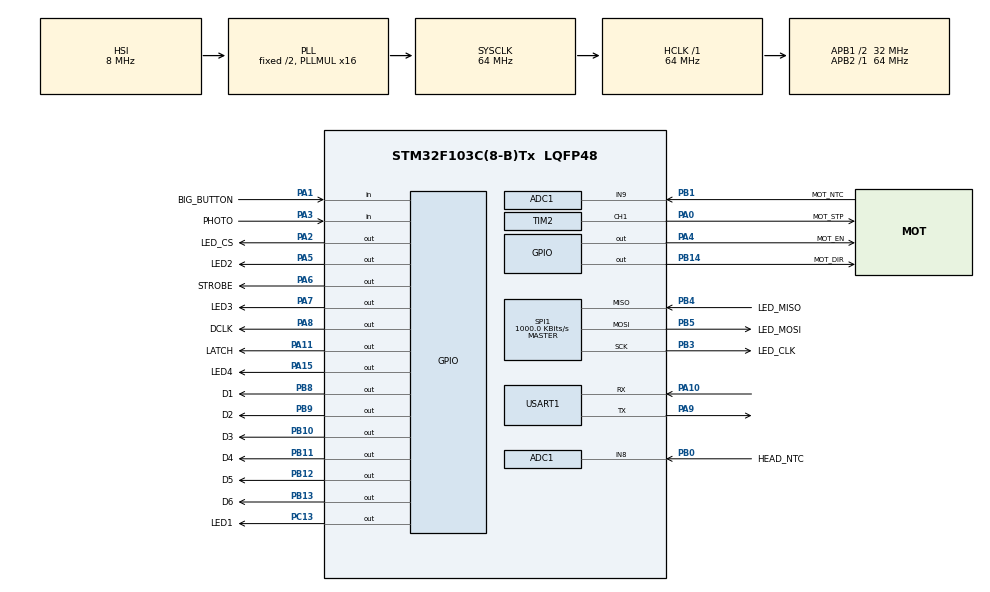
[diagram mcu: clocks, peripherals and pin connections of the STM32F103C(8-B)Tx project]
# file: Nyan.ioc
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ADC1.Channel-0\#ChannelRegularConversion=ADC_CHANNEL_8
ADC1.NbrOfConversionFlag=1
ADC1.Rank-0\#ChannelRegularConversion=1
ADC1.SamplingTime-0\#ChannelRegularConversion=ADC_SAMPLETIME_1CYCLE_5
ADC1.master=1
Dma.Request0=USART1_RX
Dma.USART1_RX.0.Direction=DMA_PERIPH_TO_MEMORY
Dma.USART1_RX.0.Instance=DMA1_Channel5
Dma.USART1_RX.0.MemDataAlignment=DMA_MDATAALIGN_BYTE
Dma.USART1_RX.0.MemInc=DMA_MINC_ENABLE
Dma.USART1_RX.0.Mode=DMA_NORMAL
Dma.USART1_RX.0.PeriphDataAlignment=DMA_PDATAALIGN_BYTE
Dma.USART1_RX.0.PeriphInc=DMA_PINC_DISABLE
Dma.USART1_RX.0.Priority=DMA_PRIORITY_LOW
Mcu.Family=STM32F1
Mcu.Name=STM32F103C(8-B)Tx
Mcu.Package=LQFP48
NVIC.DMA1_Channel5_IRQn=true\:0\:0\:false\:false\:true\:false\:true
NVIC.PriorityGroup=NVIC_PRIORITYGROUP_4
NVIC.TIM2_IRQn=true\:0\:0\:false\:false\:true\:true\:true
NVIC.TIM3_IRQn=true\:0\:0\:false\:false\:true\:true\:true
PA0-WKUP.GPIO_Label=MOT_STP
PA0-WKUP.Signal=S_TIM2_CH1_ETR
PA1.GPIO_Label=BIG_BUTTON
PA1.Signal=GPIO_Input
PA10.Mode=Asynchronous
PA10.Signal=USART1_RX
PA11.GPIO_Label=LATCH
PA11.Signal=GPIO_Output
PA13.Mode=Serial_Wire
PA13.Signal=SYS_JTMS-SWDIO
PA14.Mode=Serial_Wire
PA14.Signal=SYS_JTCK-SWCLK
PA15.GPIO_Label=LED4
PA15.Signal=GPIO_Output
PA2.GPIO_Label=LED_CS
PA2.Signal=GPIO_Output
PA3.GPIO_Label=PHOTO
PA3.Signal=GPIO_Input
PA4.GPIO_Label=MOT_EN
PA4.Signal=GPIO_Output
PA5.GPIO_Label=LED2
PA5.Signal=GPIO_Output
PA6.GPIO_Label=STROBE
PA6.Signal=GPIO_Output
PA7.GPIO_Label=LED3
PA7.Signal=GPIO_Output
PA8.GPIO_Label=DCLK
PA8.Signal=GPIO_Output
PA9.Mode=Asynchronous
PA9.Signal=USART1_TX
PB0.GPIO_Label=HEAD_NTC
PB0.Signal=ADCx_IN8
PB1.GPIO_Label=MOT_NTC
PB1.Signal=ADCx_IN9
PB10.GPIO_Label=D3
PB10.Signal=GPIO_Output
PB11.GPIO_Label=D4
PB11.Signal=GPIO_Output
PB12.GPIO_Label=D5
PB12.Signal=GPIO_Output
PB13.GPIO_Label=D6
PB13.Signal=GPIO_Output
PB14.GPIO_Label=MOT_DIR
PB14.Signal=GPIO_Output
PB3.GPIO_Label=LED_CLK
PB3.Mode=Full_Duplex_Master
PB3.Signal=SPI1_SCK
PB4.GPIO_Label=LED_MISO
PB4.Mode=Full_Duplex_Master
PB4.Signal=SPI1_MISO
PB5.GPIO_Label=LED_MOSI
PB5.Mode=Full_Duplex_Master
PB5.Signal=SPI1_MOSI
PB8.GPIO_Label=D1
PB8.Signal=GPIO_Output
PB9.GPIO_Label=D2
PB9.Signal=GPIO_Output
PC13-TAMPER-RTC.GPIO_Label=LED1
PC13-TAMPER-RTC.Signal=GPIO_Output
ProjectManager.HeapSize=0x200
ProjectManager.StackSize=0x400
ProjectManager.TargetToolchain=Makefile
RCC.ADCPresc=RCC_ADCPCLK2_DIV8
RCC.AHBFreq_Value=64000000
RCC.APB1CLKDivider=RCC_HCLK_DIV2
RCC.APB1Freq_Value=32000000
RCC.APB1TimFreq_Value=64000000
RCC.APB2Freq_Value=64000000
RCC.APB2TimFreq_Value=64000000
RCC.HCLKFreq_Value=64000000
RCC.PLLMUL=RCC_PLL_MUL16
RCC.SYSCLKFreq_VALUE=64000000
RCC.SYSCLKSource=RCC_SYSCLKSOURCE_PLLCLK
RCC.USBFreq_Value=64000000
SH.ADCx_IN8.0=ADC1_IN8,IN8
SH.ADCx_IN9.0=ADC1_IN9,IN9
SH.S_TIM2_CH1_ETR.0=TIM2_CH1,PWM Generation1 CH1
SPI1.BaudRatePrescaler=SPI_BAUDRATEPRESCALER_64
SPI1.CalculateBaudRate=1000.0 KBits/s
SPI1.Direction=SPI_DIRECTION_2LINES
SPI1.Mode=SPI_MODE_MASTER
SPI1.VirtualType=VM_MASTER
TIM2.AutoReloadPreload=TIM_AUTORELOAD_PRELOAD_ENABLE
TIM2.Channel-PWM\ Generation1\ CH1=TIM_CHANNEL_1
TIM2.Period=32000
TIM2.Prescaler=1999
TIM2.Pulse-PWM\ Generation1\ CH1=16000
TIM3.Period=10000
TIM3.Prescaler=639
USART1.VirtualMode=VM_ASYNC
VP_TIM2_VS_ClockSourceINT.Mode=Internal
VP_TIM3_VS_ClockSourceINT.Mode=Internal
VP_TIM3_VS_OPM.Mode=OPM_bit
board=custom

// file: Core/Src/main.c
/* USER CODE BEGIN Header */
/**
  ******************************************************************************
  * @file           : main.c
  * @brief          : Main program body
  ******************************************************************************
  * @attention
  *
  * <h2><center>&copy; Copyright (c) 2021 STMicroelectronics.
  * All rights reserved.</center></h2>
  *
  * This software component is licensed by ST under BSD 3-Clause license,
  * the "License"; You may not use this file except in compliance with the
  * License. You may obtain a copy of the License at:
  *                        opensource.org/licenses/BSD-3-Clause
  *
  ******************************************************************************
  */
/* USER CODE END Header */
#include "main.h"
#include "adc.h"
#include "dma.h"
#include "spi.h"
#include "tim.h"
#include "usart.h"
#include "gpio.h"

/* USER CODE BEGIN Includes */
#include "system.h"
/* USER CODE END Includes */

void SystemClock_Config(void);

int main(void)
{

  /* MCU Configuration--------------------------------------------------------*/

  /* Reset of all peripherals, Initializes the Flash interface and the Systick. */
  HAL_Init();

  /* Configure the system clock */
  SystemClock_Config();

  /* Initialize all configured peripherals */
  MX_GPIO_Init();
  MX_DMA_Init();
  MX_USART1_UART_Init();
  MX_ADC1_Init();
  MX_SPI1_Init();
  MX_TIM2_Init();
  MX_TIM3_Init();
  /* USER CODE BEGIN 2 */
  System_Init();
  /* USER CODE END 2 */

  /* Infinite loop */
  while (1)
  {

    /* USER CODE BEGIN 3 */
    System_MainRoutine();
  }
  /* USER CODE END 3 */
}

void SystemClock_Config(void)
{
  RCC_OscInitTypeDef RCC_OscInitStruct = {0};
  RCC_ClkInitTypeDef RCC_ClkInitStruct = {0};
  RCC_PeriphCLKInitTypeDef PeriphClkInit = {0};

  /** Initializes the RCC Oscillators according to the specified parameters
  * in the RCC_OscInitTypeDef structure.
  */
  RCC_OscInitStruct.OscillatorType = RCC_OSCILLATORTYPE_HSI;
  RCC_OscInitStruct.HSIState = RCC_HSI_ON;
  RCC_OscInitStruct.HSICalibrationValue = RCC_HSICALIBRATION_DEFAULT;
  RCC_OscInitStruct.PLL.PLLState = RCC_PLL_ON;
  RCC_OscInitStruct.PLL.PLLSource = RCC_PLLSOURCE_HSI_DIV2;
  RCC_OscInitStruct.PLL.PLLMUL = RCC_PLL_MUL16;
  if (HAL_RCC_OscConfig(&RCC_OscInitStruct) != HAL_OK)
  {
    Error_Handler();
  }
  /** Initializes the CPU, AHB and APB buses clocks
  */
  RCC_ClkInitStruct.ClockType = RCC_CLOCKTYPE_HCLK|RCC_CLOCKTYPE_SYSCLK
                              |RCC_CLOCKTYPE_PCLK1|RCC_CLOCKTYPE_PCLK2;
  RCC_ClkInitStruct.SYSCLKSource = RCC_SYSCLKSOURCE_PLLCLK;
  RCC_ClkInitStruct.AHBCLKDivider = RCC_SYSCLK_DIV1;
  RCC_ClkInitStruct.APB1CLKDivider = RCC_HCLK_DIV2;
  RCC_ClkInitStruct.APB2CLKDivider = RCC_HCLK_DIV1;

  if (HAL_RCC_ClockConfig(&RCC_ClkInitStruct, FLASH_LATENCY_2) != HAL_OK)
  {
    Error_Handler();
  }
  PeriphClkInit.PeriphClockSelection = RCC_PERIPHCLK_ADC;
  PeriphClkInit.AdcClockSelection = RCC_ADCPCLK2_DIV8;
  if (HAL_RCCEx_PeriphCLKConfig(&PeriphClkInit) != HAL_OK)
  {
    Error_Handler();
  }
}

void Error_Handler(void)
{
  __disable_irq();
  while (1)
  {
  }
}

/************************ (C) COPYRIGHT STMicroelectronics *****END OF FILE****/
